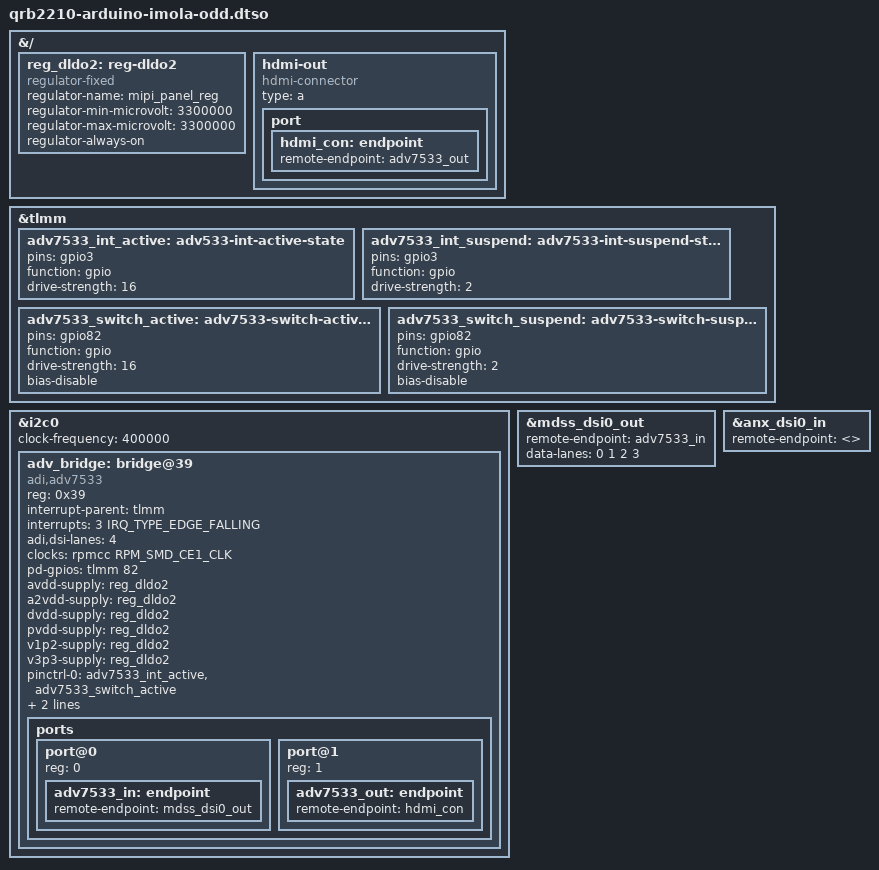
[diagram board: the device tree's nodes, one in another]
// SPDX-License-Identifier: (GPL-2.0+ OR BSD-3-Clause)
/*
 * Copyright (c) 2025, Arduino SA
 */

/dts-v1/;
/plugin/;

#include <dt-bindings/gpio/gpio.h>
#include <dt-bindings/interrupt-controller/arm-gic.h>
#include <dt-bindings/clock/qcom,rpmcc.h>

&{/} {
	reg_dldo2: reg-dldo2 {
		compatible = "regulator-fixed";
		regulator-name = "mipi_panel_reg";
		regulator-min-microvolt = <3300000>;
		regulator-max-microvolt = <3300000>;
		regulator-always-on;
	};

	hdmi-out {
		compatible = "hdmi-connector";
		type = "a";

		port {
			hdmi_con: endpoint {
				remote-endpoint = <&adv7533_out>;
			};
		};
	};
};

&tlmm {
	adv7533_int_active: adv533-int-active-state {
		pins = "gpio3";
		function = "gpio";
		drive-strength = <16>;
	};

	adv7533_int_suspend: adv7533-int-suspend-state {
		pins = "gpio3";
		function = "gpio";
		drive-strength = <2>;
	};

	adv7533_switch_active: adv7533-switch-active-state {
		pins = "gpio82";
		function = "gpio";
		drive-strength = <16>;
		bias-disable;
	};

	adv7533_switch_suspend: adv7533-switch-suspend-state {
		pins = "gpio82";
		function = "gpio";
		drive-strength = <2>;
		bias-disable;
	};
};

&i2c0 {
	status = "okay";
	clock-frequency = <400000>;
	/delete-property/ dmas;

	adv_bridge: bridge@39 {
		status = "okay";

		compatible = "adi,adv7533";
		reg = <0x39>;

		interrupt-parent = <&tlmm>;
		interrupts = <3 IRQ_TYPE_EDGE_FALLING>;

		adi,dsi-lanes = <4>;

		clocks = <&rpmcc RPM_SMD_CE1_CLK>;
		clock-names = "cec";

		pd-gpios = <&tlmm 82 GPIO_ACTIVE_HIGH>;

		avdd-supply = <&reg_dldo2>;
		a2vdd-supply = <&reg_dldo2>;
		dvdd-supply = <&reg_dldo2>;
		pvdd-supply = <&reg_dldo2>;
		v1p2-supply = <&reg_dldo2>;
		v3p3-supply = <&reg_dldo2>;

		pinctrl-names = "default","sleep";
		pinctrl-0 = <&adv7533_int_active &adv7533_switch_active>;
		pinctrl-1 = <&adv7533_int_suspend &adv7533_switch_suspend>;

		ports {
			#address-cells = <1>;
			#size-cells = <0>;

			port@0 {
				reg = <0>;
				adv7533_in: endpoint {
					remote-endpoint = <&mdss_dsi0_out>;
				};
			};

			port@1 {
				reg = <1>;
				adv7533_out: endpoint {
					remote-endpoint = <&hdmi_con>;
				};
			};
		};
	};
};

&mdss_dsi0_out {
	remote-endpoint = <&adv7533_in>;
	data-lanes = <0 1 2 3>;
};

&anx_dsi0_in {
	remote-endpoint = <>;
};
